# MCU_R5FSS0_COMMON0_EVNT_BUS_VBUSP_MMRS register map
Vendor: Texas Instruments
Peripheral module from a debugger description file (folder J7_AHP).
Registers are 32-bit, read-only, reset 0x0 unless marked. A register's access mark holds for its fields unless they carry their own. Offsets are as the file gives them; lines under a group give offsets from that group; [hi:lo] are bit positions; {n}, {i} and the like mark numbered series; 'fields as' and 'values as' point back to an identical list; <NAME> marks a mode.

## MCU_R5FSS0_COMMON0_EVNT_BUS_VBUSP_MMRS
0x00 EVNT_BUS__VBUSP__MMRS_DISABLE_CR rw
  [0] COMBINE_TCM_LOCKSTEP_MODE — this bit disables the CR logic to combine TCM in lockstep mode
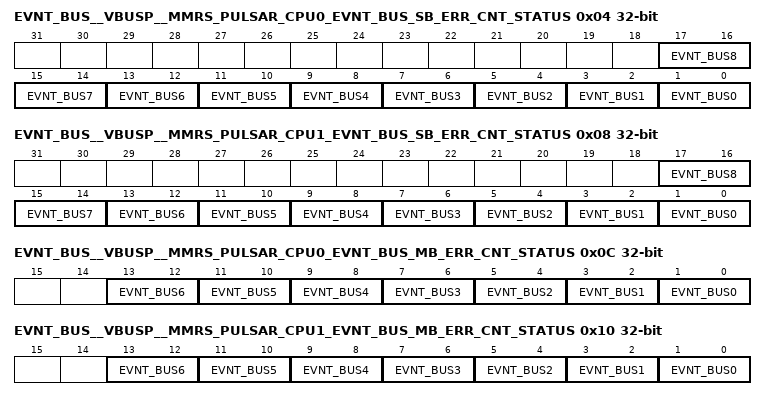
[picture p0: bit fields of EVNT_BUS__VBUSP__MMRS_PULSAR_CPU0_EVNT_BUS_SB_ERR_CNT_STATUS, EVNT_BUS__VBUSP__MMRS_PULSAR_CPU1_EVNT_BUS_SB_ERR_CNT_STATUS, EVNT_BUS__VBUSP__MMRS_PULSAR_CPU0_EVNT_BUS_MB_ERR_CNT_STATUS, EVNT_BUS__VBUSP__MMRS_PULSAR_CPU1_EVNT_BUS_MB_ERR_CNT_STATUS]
0x04 EVNT_BUS__VBUSP__MMRS_PULSAR_CPU0_EVNT_BUS_SB_ERR_CNT_STATUS
  [2n+1:2n] EVNT_BUS{n} (n=0..8) — Status bits showing the PULSAR CPU0 EVNT {n} single bit error counter.
0x08 EVNT_BUS__VBUSP__MMRS_PULSAR_CPU1_EVNT_BUS_SB_ERR_CNT_STATUS
  [2n+1:2n] EVNT_BUS{n} (n=0..8) — Status bits showing the PULSAR CPU1 EVNT {n} single bit error counter.
0x0C EVNT_BUS__VBUSP__MMRS_PULSAR_CPU0_EVNT_BUS_MB_ERR_CNT_STATUS
  [2n+1:2n] EVNT_BUS{n} (n=0..6) — Status bits showing the PULSAR CPU0 EVNT {n} multi bit error counter.
0x10 EVNT_BUS__VBUSP__MMRS_PULSAR_CPU1_EVNT_BUS_MB_ERR_CNT_STATUS
  [2n+1:2n] EVNT_BUS{n} (n=0..6) — Status bits showing the PULSAR CPU1 EVNT {n} multi bit error counter.
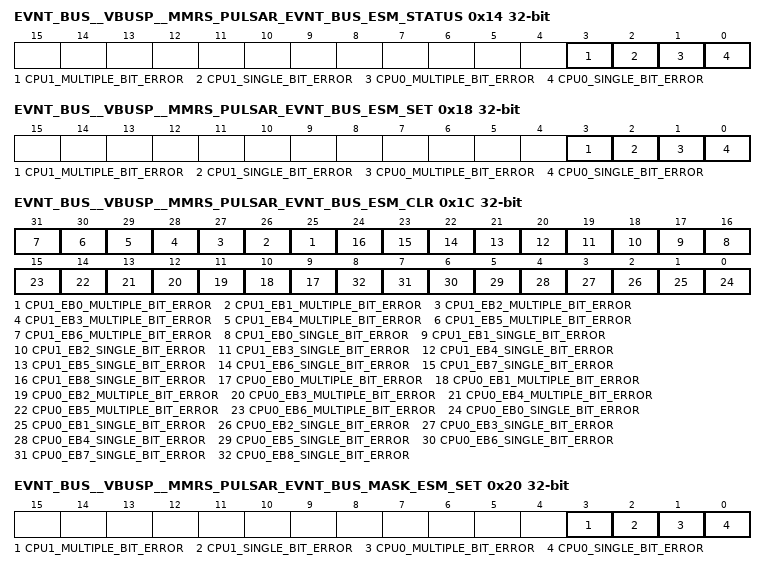
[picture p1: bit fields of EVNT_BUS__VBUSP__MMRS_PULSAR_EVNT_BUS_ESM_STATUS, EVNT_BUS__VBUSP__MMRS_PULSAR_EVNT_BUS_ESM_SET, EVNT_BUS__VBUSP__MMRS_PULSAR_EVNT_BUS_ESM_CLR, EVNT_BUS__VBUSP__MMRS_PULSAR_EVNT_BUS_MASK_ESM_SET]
0x14 EVNT_BUS__VBUSP__MMRS_PULSAR_EVNT_BUS_ESM_STATUS
  [3] CPU1_MULTIPLE_BIT_ERROR — ESM status of CPU1 multiple bit errors on EVNT BUS
  [2] CPU1_SINGLE_BIT_ERROR — ESM status of CPU1 single bit errors on EVNT BUS
  [1] CPU0_MULTIPLE_BIT_ERROR — ESM status of CPU0 multiple bit errors on EVNT BUS
  [0] CPU0_SINGLE_BIT_ERROR — ESM status of CPU0 single bit errors on EVNT BUS
0x18 EVNT_BUS__VBUSP__MMRS_PULSAR_EVNT_BUS_ESM_SET access not given
  [3] CPU1_MULTIPLE_BIT_ERROR — SET CPU1 multiple bit errors ESM event (access R/W1TS)
  [2] CPU1_SINGLE_BIT_ERROR — SET CPU1 single bit errors ESM event (access R/W1TS)
  [1] CPU0_MULTIPLE_BIT_ERROR — SET CPU0 multiple bit error ESM event (access R/W1TS)
  [0] CPU0_SINGLE_BIT_ERROR — SET CPU0 single bit error ESM event (access R/W1TS)
0x1C EVNT_BUS__VBUSP__MMRS_PULSAR_EVNT_BUS_ESM_CLR access not given
  [n+25] CPU1_EB{n}_MULTIPLE_BIT_ERROR (n=0..6) — Decrement CPU1 Event Bus {n+25} MULTIPLE BIT Error Counter (access R/W1TD)
  [n+16] CPU1_EB{n}_SINGLE_BIT_ERROR (n=0..8) — Decrement CPU1 Event Bus {n+16} SINGLE BIT Error Counter (access R/W1TD)
  [n+9] CPU0_EB{n}_MULTIPLE_BIT_ERROR (n=0..6) — Decrement CPU0 Event Bus {n+9} MULTIPLE BIT Error Counter (access R/W1TD)
  [n] CPU0_EB{n}_SINGLE_BIT_ERROR (n=0..8) — Decrement CPU0 Event Bus {n} SINGLE BIT Error Counter (access R/W1TD)
0x20 EVNT_BUS__VBUSP__MMRS_PULSAR_EVNT_BUS_MASK_ESM_SET access not given
  [3] CPU1_MULTIPLE_BIT_ERROR — MASK CPU1 multiple bit errors ESM event (access R/W1TS)
  [2] CPU1_SINGLE_BIT_ERROR — MASK CPU1 single bit errors ESM event (access R/W1TS)
  [1] CPU0_MULTIPLE_BIT_ERROR — MASK CPU0 multiple bit error ESM event (access R/W1TS)
  [0] CPU0_SINGLE_BIT_ERROR — MASK CPU0 single bit error ESM event (access R/W1TS)
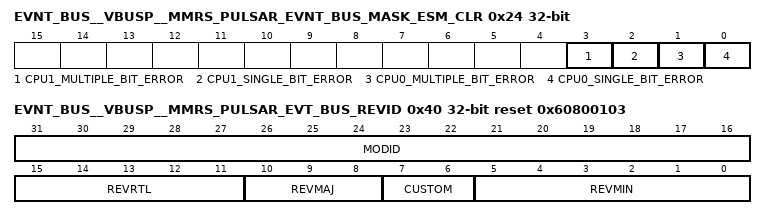
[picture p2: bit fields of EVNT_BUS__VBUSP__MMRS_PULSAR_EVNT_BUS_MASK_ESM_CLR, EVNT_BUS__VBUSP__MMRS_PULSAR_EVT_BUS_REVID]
0x24 EVNT_BUS__VBUSP__MMRS_PULSAR_EVNT_BUS_MASK_ESM_CLR access not given
  [3] CPU1_MULTIPLE_BIT_ERROR — UNMASK CPU1 multiple bit errors ESM event (access R/W1TC)
  [2] CPU1_SINGLE_BIT_ERROR — UNMASK CPU1 single bit errors ESM event (access R/W1TC)
  [1] CPU0_MULTIPLE_BIT_ERROR — UNMASK CPU0 multiple bit error ESM event (access R/W1TC)
  [0] CPU0_SINGLE_BIT_ERROR — UNMASK CPU0 single bit error ESM event (access R/W1TC)
0x40 EVNT_BUS__VBUSP__MMRS_PULSAR_EVT_BUS_REVID reset 0x60800103
  [31:16] MODID — Module ID field
  [15:11] REVRTL — RTL revision. Will vary depending on release
  [10:8] REVMAJ — Major revision
  [7:6] CUSTOM
  [5:0] REVMIN — Minor revision
